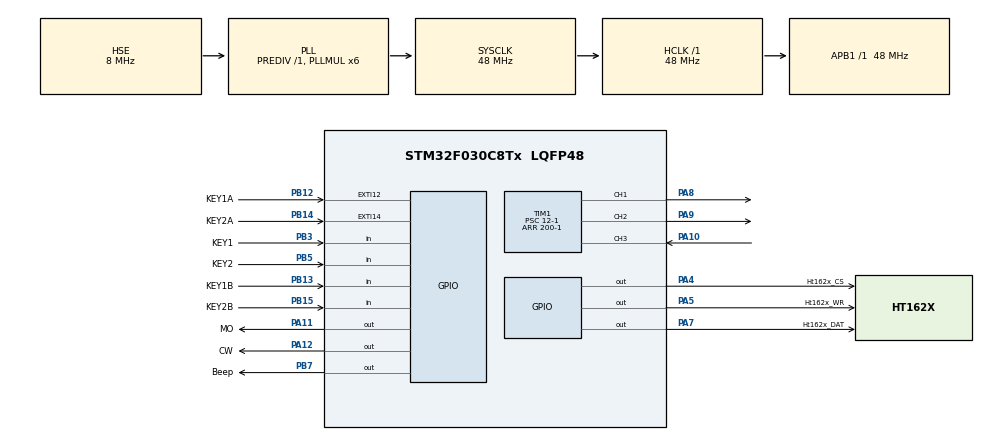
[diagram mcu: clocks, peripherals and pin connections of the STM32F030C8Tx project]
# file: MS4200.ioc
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Mcu.Family=STM32F0
Mcu.Name=STM32F030C8Tx
Mcu.Package=LQFP48
NVIC.EXTI4_15_IRQn=true\:1\:0\:true\:false\:true\:true\:true\:true
NVIC.TIM14_IRQn=true\:2\:0\:true\:false\:true\:true\:true\:true
NVIC.TIM1_BRK_UP_TRG_COM_IRQn=true\:2\:0\:true\:false\:true\:true\:true\:true
NVIC.TIM1_CC_IRQn=true\:2\:0\:true\:false\:true\:true\:true\:true
NVIC.TIM6_IRQn=true\:2\:0\:true\:false\:true\:true\:true\:true
PA10.Signal=S_TIM1_CH3
PA11.GPIO_Label=MO
PA11.GPIO_PuPd=GPIO_PULLDOWN
PA11.GPIO_Speed=GPIO_SPEED_FREQ_HIGH
PA11.PinState=GPIO_PIN_RESET
PA11.Signal=GPIO_Output
PA12.GPIO_Label=CW
PA12.GPIO_PuPd=GPIO_PULLDOWN
PA12.Signal=GPIO_Output
PA13.Mode=Serial_Wire
PA13.Signal=SYS_SWDIO
PA14.Mode=Serial_Wire
PA14.Signal=SYS_SWCLK
PA4.GPIO_Label=Ht162x_CS
PA4.GPIO_PuPd=GPIO_PULLUP
PA4.GPIO_Speed=GPIO_SPEED_FREQ_HIGH
PA4.PinState=GPIO_PIN_SET
PA4.Signal=GPIO_Output
PA5.GPIO_Label=Ht162x_WR
PA5.GPIO_PuPd=GPIO_PULLUP
PA5.GPIO_Speed=GPIO_SPEED_FREQ_HIGH
PA5.PinState=GPIO_PIN_SET
PA5.Signal=GPIO_Output
PA7.GPIO_Label=Ht162x_DAT
PA7.GPIO_PuPd=GPIO_PULLUP
PA7.GPIO_Speed=GPIO_SPEED_FREQ_HIGH
PA7.PinState=GPIO_PIN_SET
PA7.Signal=GPIO_Output
PA8.Signal=S_TIM1_CH1
PA9.Signal=S_TIM1_CH2
PB12.GPIO_Label=KEY1A
PB12.GPIO_ModeDefaultEXTI=GPIO_MODE_IT_RISING_FALLING
PB12.GPIO_PuPd=GPIO_PULLUP
PB12.Signal=GPXTI12
PB13.GPIO_Label=KEY1B
PB13.GPIO_PuPd=GPIO_PULLUP
PB13.Signal=GPIO_Input
PB14.GPIO_Label=KEY2A
PB14.GPIO_ModeDefaultEXTI=GPIO_MODE_IT_RISING_FALLING
PB14.GPIO_PuPd=GPIO_PULLUP
PB14.Signal=GPXTI14
PB15.GPIO_Label=KEY2B
PB15.GPIO_PuPd=GPIO_PULLUP
PB15.Signal=GPIO_Input
PB3.GPIO_Label=KEY1
PB3.Signal=GPIO_Input
PB5.GPIO_Label=KEY2
PB5.Signal=GPIO_Input
PB7.GPIO_Label=Beep
PB7.GPIO_PuPd=GPIO_PULLDOWN
PB7.Signal=GPIO_Output
PF0-OSC_IN.Mode=HSE-External-Oscillator
PF0-OSC_IN.Signal=RCC_OSC_IN
PF1-OSC_OUT.Mode=HSE-External-Oscillator
PF1-OSC_OUT.Signal=RCC_OSC_OUT
ProjectManager.HeapSize=0x200
ProjectManager.StackSize=0x400
ProjectManager.TargetToolchain=MDK-ARM V5.32
RCC.AHBFreq_Value=48000000
RCC.APB1Freq_Value=48000000
RCC.APB1TimFreq_Value=48000000
RCC.HCLKFreq_Value=48000000
RCC.PLLMUL=RCC_PLL_MUL6
RCC.PLLSourceVirtual=RCC_PLLSOURCE_HSE
RCC.SYSCLKFreq_VALUE=48000000
RCC.SYSCLKSource=RCC_SYSCLKSOURCE_PLLCLK
SH.S_TIM1_CH1.0=TIM1_CH1,PWM Generation1 CH1
SH.S_TIM1_CH2.0=TIM1_CH2,PWM Generation2 CH2
SH.S_TIM1_CH3.0=TIM1_CH3,Input_Capture3_from_TI3
TIM1.Channel-Input_Capture3_from_TI3=TIM_CHANNEL_3
TIM1.Channel-PWM\ Generation1\ CH1=TIM_CHANNEL_1
TIM1.Channel-PWM\ Generation2\ CH2=TIM_CHANNEL_2
TIM1.ICFilter_CH3=0
TIM1.Period=200-1
TIM1.Prescaler=12-1
TIM14.AutoReloadPreload=TIM_AUTORELOAD_PRELOAD_ENABLE
TIM14.Period=100-1
TIM14.Prescaler=480-1
TIM6.AutoReloadPreload=TIM_AUTORELOAD_PRELOAD_ENABLE
TIM6.Period=100-1
TIM6.Prescaler=480-1
VP_TIM14_VS_ClockSourceINT.Mode=Enable_Timer
VP_TIM1_VS_ClockSourceINT.Mode=Internal
VP_TIM6_VS_ClockSourceINT.Mode=Enable_Timer
board=custom

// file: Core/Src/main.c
/* USER CODE BEGIN Header */
/**
  ******************************************************************************
  * @file           : main.c
  * @brief          : Main program body
  ******************************************************************************
  * @attention
  *
  * <h2><center>&copy; Copyright (c) 2023 STMicroelectronics.
  * All rights reserved.</center></h2>
  *
  * This software component is licensed by ST under BSD 3-Clause license,
  * the "License"; You may not use this file except in compliance with the
  * License. You may obtain a copy of the License at:
  *                        opensource.org/licenses/BSD-3-Clause
  *
  ******************************************************************************
  */
/* USER CODE END Header */
#include "main.h"
#include "tim.h"
#include "gpio.h"

void SystemClock_Config(void);

int main(void)
{

  /* MCU Configuration--------------------------------------------------------*/

  /* Reset of all peripherals, Initializes the Flash interface and the Systick. */
  HAL_Init();

  /* Configure the system clock */
  SystemClock_Config();

  /* Initialize all configured peripherals */
  MX_GPIO_Init();
  MX_TIM1_Init();
  MX_TIM6_Init();
  MX_TIM14_Init();
  /* USER CODE BEGIN 2 */
    System_Init();//ϵͳ������ʼ��
  /* USER CODE END 2 */

  /* Infinite loop */
  while (1)
  {

    /* USER CODE BEGIN 3 */
    TIM1_Poll();//���״̬
	Show_Display();//��ʾ��Ļ����
  }
  /* USER CODE END 3 */
}

void SystemClock_Config(void)
{
  RCC_OscInitTypeDef RCC_OscInitStruct = {0};
  RCC_ClkInitTypeDef RCC_ClkInitStruct = {0};

  /** Initializes the RCC Oscillators according to the specified parameters
  * in the RCC_OscInitTypeDef structure.
  */
  RCC_OscInitStruct.OscillatorType = RCC_OSCILLATORTYPE_HSE;
  RCC_OscInitStruct.HSEState = RCC_HSE_ON;
  RCC_OscInitStruct.PLL.PLLState = RCC_PLL_ON;
  RCC_OscInitStruct.PLL.PLLSource = RCC_PLLSOURCE_HSE;
  RCC_OscInitStruct.PLL.PLLMUL = RCC_PLL_MUL6;
  RCC_OscInitStruct.PLL.PREDIV = RCC_PREDIV_DIV1;
  if (HAL_RCC_OscConfig(&RCC_OscInitStruct) != HAL_OK)
  {
    Error_Handler();
  }
  /** Initializes the CPU, AHB and APB buses clocks
  */
  RCC_ClkInitStruct.ClockType = RCC_CLOCKTYPE_HCLK|RCC_CLOCKTYPE_SYSCLK
                              |RCC_CLOCKTYPE_PCLK1;
  RCC_ClkInitStruct.SYSCLKSource = RCC_SYSCLKSOURCE_PLLCLK;
  RCC_ClkInitStruct.AHBCLKDivider = RCC_SYSCLK_DIV1;
  RCC_ClkInitStruct.APB1CLKDivider = RCC_HCLK_DIV1;

  if (HAL_RCC_ClockConfig(&RCC_ClkInitStruct, FLASH_LATENCY_1) != HAL_OK)
  {
    Error_Handler();
  }
}

void Error_Handler(void)
{
  __disable_irq();
  while (1)
  {
  }
}

/************************ (C) COPYRIGHT STMicroelectronics *****END OF FILE****/
